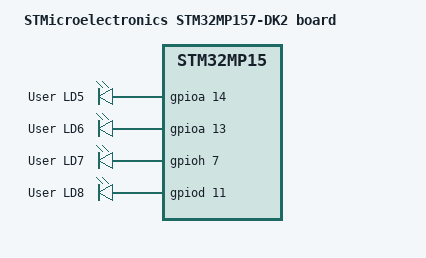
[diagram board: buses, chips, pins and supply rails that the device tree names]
/*
 * Copyright (c) 2019 STMicroelectronics
 *
 * SPDX-License-Identifier: Apache-2.0
 */

/dts-v1/;
#include <st/mp1/stm32mp157.dtsi>

/ {
	model = "STMicroelectronics STM32MP157-DK2  board";
	compatible = "st,stm32mp157c-dk2", "st,stm32mp15";
	chosen {
		zephyr,flash = &retram;
		zephyr,sram = &mcusram;
	};

	leds {
		compatible = "gpio-leds";
		green_led_1: LD5 {
			gpios = <&gpioa 14 GPIO_INT_ACTIVE_HIGH>;
			label = "User LD5";
		};
		red_led_1: LD6 {
			gpios = <&gpioa 13 GPIO_INT_ACTIVE_HIGH>;
			label = "User LD6";
		};
		yellow_led_1: LD7 {
			gpios = <&gpioh 7 GPIO_INT_ACTIVE_HIGH>;
			label = "User LD7";
		};
		blue_led_1: LD8 {
			gpios = <&gpiod 11 GPIO_INT_ACTIVE_HIGH>;
			label = "User LD8";
		};
	};

	aliases {
		led0 = &yellow_led_1;
	};
};
